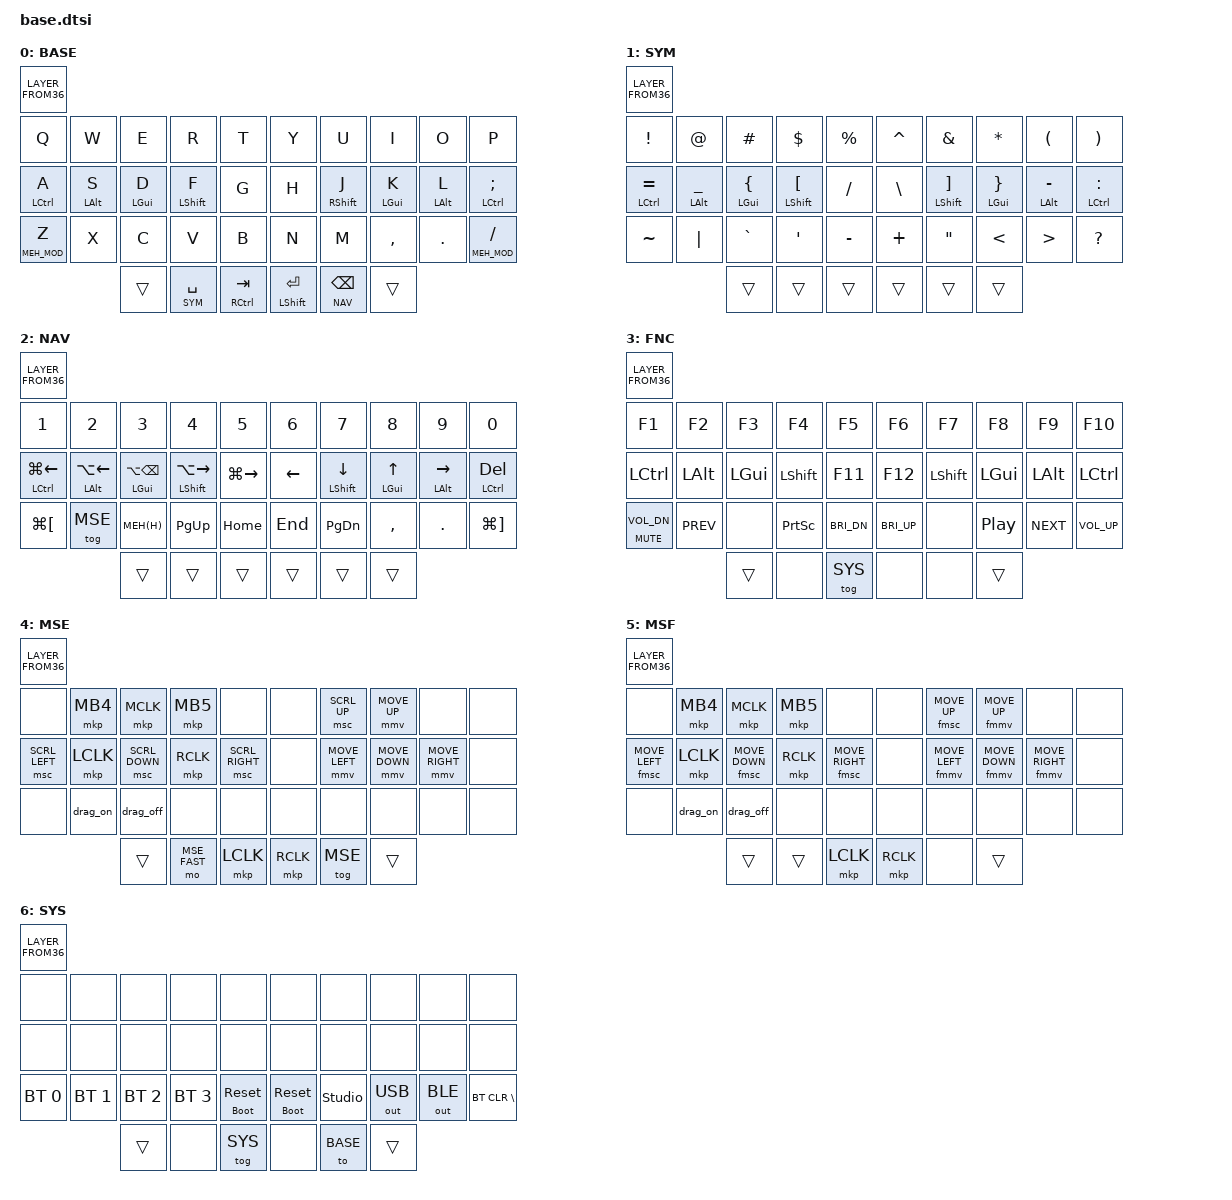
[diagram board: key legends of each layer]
#include <behaviors.dtsi>
#include <dt-bindings/zmk/keys.h>
#include <dt-bindings/zmk/bt.h>
#include <dt-bindings/zmk/outputs.h>
#include <behaviors/rgbled_widget.dtsi> // rgb led indicator for battery and connection

// Layer definitions
#define BASE 0
#define SYM 1
#define NAV 2
#define FNC 3
#define MSE 4
#define MSE_FAST 5
#define SYS 6

#define MEH(k) LC(LA(LS(k)))
#define MEH_MOD LA(LS(LCTRL))

#include "mouse.dtsi"
#include "combos.dtsi"

&caps_word { continue-list = <UNDERSCORE BACKSPACE DELETE MINUS DEL N1 N2 N3 N4 N5 N6 N7 N8 N9 N0>; };

/ {
    macros {
        drag_on: drag_on {
            compatible = "zmk,behavior-macro";
            #binding-cells = <0>;
            bindings = <&macro_press &mkp LCLK>;
        };

        drag_off: drag_off {
            compatible = "zmk,behavior-macro";
            #binding-cells = <0>;
            bindings = <&macro_release &mkp LCLK>;
        };
    };

   cond_layers {
        compatible = "zmk,conditional-layers";
        // Define FNC layer as tri-state
        func_tristate {
            if-layers = <SYM NAV>;
            then-layer = <FNC>;
        };
    };

    behaviors {
        hmr: hmr {
            compatible = "zmk,behavior-hold-tap";
            bindings = <&kp>, <&kp>;

            #binding-cells = <2>;
            tapping-term-ms = <230>;
            quick-tap-ms = <150>;
            require-prior-idle-ms = <130>;
            flavor = "balanced";
            hold-trigger-key-positions = <KEYS_L THUMBS>;
            hold-trigger-on-release;
        };

        hml: hml {
            compatible = "zmk,behavior-hold-tap";
            bindings = <&kp>, <&kp>;

            #binding-cells = <2>;
            tapping-term-ms = <230>;
            quick-tap-ms = <155>;
            require-prior-idle-ms = <130>;
            flavor = "balanced";
            hold-trigger-key-positions = <KEYS_R LH0 RH0 RH1>;
            hold-trigger-on-release;
        };

        rth: rthumb {
            compatible = "zmk,behavior-hold-tap";
            bindings = <&mo>, <&kp>;
            flavor = "hold-preferred";
            #binding-cells = <2>;
            tapping-term-ms = <200>;
            quick-tap-ms = <130>;
        };

        lth: lthumb {
            compatible = "zmk,behavior-hold-tap";
            bindings = <&mo>, <&kp>;
            flavor = "hold-preferred";
            #binding-cells = <2>;
            tapping-term-ms = <230>;
            quick-tap-ms = <140>;
        };

        hp: hold_priority {
            compatible = "zmk,behavior-hold-tap";
            bindings = <&kp>, <&kp>;
            flavor = "hold-preferred";
            #binding-cells = <2>;
            tapping-term-ms = <230>;
            quick-tap-ms = <150>;
        };

        lsm: left_shift_mode {
            compatible = "zmk,behavior-hold-tap";
            bindings = <&kp>, <&kp>;
            flavor = "hold-preferred";
            #binding-cells = <2>;
            tapping-term-ms = <190>;
            quick-tap-ms = <150>;
            require-prior-idle-ms = <120>;
            hold-trigger-key-positions = <KEYS_R LH0 RH0>;
            //hold-trigger-on-release;
        };

        rsm: right_shift_mode {
            compatible = "zmk,behavior-hold-tap";
            bindings = <&kp>, <&kp>;
            flavor = "hold-preferred";
            #binding-cells = <2>;
            tapping-term-ms = <190>;
            quick-tap-ms = <150>;
            require-prior-idle-ms = <130>;
            hold-trigger-key-positions = <KEYS_L LH0 RH0>;
            //hold-trigger-on-release;
        };

        rst_boot: rst_boot {
            compatible = "zmk,behavior-hold-tap";
            #binding-cells = <2>;
            tapping-term-ms = <800>;
            flavor = "tap-preferred";
            bindings = <&bootloader>, <&sys_reset>; // Press-> sys_reset, hold-> bootloader
        };

    };

    keymap {
        compatible = "zmk,keymap";

        base {
            display-name = "BASE";
            bindings = <LAYER_FROM36( \
// ╭─────────────┬─────────────┬─────────────┬─────────────┬─────────────╮   ╭───────────────┬───────────────┬───────────────┬─────────────┬───────────────╮
     &kp Q,        &kp W,        &kp E,        &kp R,        &kp T,            &kp Y,           &kp U,          &kp I,        &kp O,           &kp P,      \
// ├─────────────┼─────────────┼─────────────┼─────────────┼─────────────┤   ├───────────────┼───────────────┼───────────────┼─────────────┼───────────────┤
     &hml LCTRL A, &hml LALT S,  &hml LGUI D,  &lsm LSHFT F, &kp G,            &kp H,           &rsm RSHFT J, &hmr LGUI K,    &hmr LALT L,  &hmr LCTRL SEMI,\
// ├─────────────┼─────────────┼─────────────┼─────────────┼─────────────┤   ├───────────────┼───────────────┼───────────────┼─────────────┼───────────────┤
     &hml MEH_MOD Z,             &kp X,        &kp C,        &kp V,        &kp B,            &kp N,           &kp M,          &kp COMMA,      &kp DOT,     &hmr MEH_MOD SLASH, \
// ╰─────────────┴─────────────┴─────────────┼─────────────┼─────────────┤   ├───────────────┼───────────────┼───────────────┴─────────────┴───────────────╯
                                 &trans,      &lth SYM SPACE, &hp RCTRL TAB,  &hp LSHFT ENTER,  &rth NAV BSPC,   &trans
//                             ╰─────────────┴─────────────┴─────────────╯   ╰───────────────┴───────────────┴─────────────╯
            )>;
        };

        symbol {
          display-name = "SYM";
          bindings = <LAYER_FROM36( \
// ╭───────────────┬───────────────┬───────────────┬────────────────────┬───────────────╮   ╭───────────────┬────────────────────┬────────────────────┬────────────────────┬────────────────────╮
    &kp EXCL,        &kp AT_SIGN,     &kp HASH,        &kp DLLR,           &kp PRCNT,         &kp CARET,       &kp AMPS,            &kp ASTERISK,          &kp LPAR,             &kp RPAR,      \
// ├───────────────┼───────────────┼───────────────┼────────────────────┼───────────────┤   ├───────────────┼────────────────────┼────────────────────┼────────────────────┼────────────────────┤
   &hml LCTRL EQUAL, &hml LALT UNDER, &hml LGUI LBRC, &hml LSHFT LBKT,    &kp SLASH,          &kp BSLH,        &hmr LSHFT RBKT,    &hmr LGUI RBRC,       &hmr LALT MINUS,     &hmr LCTRL COLON, \
// ├───────────────┼───────────────┼───────────────┼────────────────────┼───────────────┤   ├───────────────┼────────────────────┼────────────────────┼────────────────────┼────────────────────┤
      &kp TILDE,       &kp PIPE,       &kp GRAVE,       &kp SQT,            &kp MINUS,         &kp PLUS,        &kp DOUBLE_QUOTES,  &kp LESS_THAN,       &kp GREATER_THAN,     &kp QUESTION,    \
// ╰───────────────┴───────────────┴───────────────┼────────────────────┼───────────────┤   ├───────────────┼────────────────────┴────────────────────┴────────────────────┴────────────────────╯
                                       &trans,          &trans,             &trans,              &trans,        &trans,             &trans       \
//                                 ╰───────────────┴────────────────────┴───────────────╯   ╰───────────────┴────────────────────┴───────────────╯
         )>;
      };

        nav_number {
            display-name = "NAV";
            bindings = <LAYER_FROM36( \
// ╭──────────────────┬───────────────┬────────────────────┬─────────────────┬──────────────╮   ╭────────────────────┬─────────────────┬───────────────┬──────────────────┬─────────────────────╮
     &kp N1,               &kp N2,      &kp N3,              &kp N4,           &kp N5,             &kp N6,             &kp N7,            &kp N8,        &kp N9,            &kp N0,             \
// ├──────────────────┼───────────────┼────────────────────┼─────────────────┼──────────────┤   ├────────────────────┼─────────────────┼───────────────┼──────────────────┼─────────────────────┤
     &hml LCTRL LG(LEFT), &hml LALT LA(LEFT), &hml LGUI LA(BSPC),  &lsm LSHFT LA(RIGHT),  &kp LG(RIGHT),            &kp LEFT,           &hmr LSHFT DOWN,   &hmr LGUI UP,  &hmr LALT RIGHT,   &hmr LCTRL DEL,\
// ├──────────────────┼───────────────┼────────────────────┼─────────────────┼──────────────┤   ├────────────────────┼─────────────────┼───────────────┼──────────────────┼─────────────────────┤
     &kp LG(LBKT),        &tog MSE,      &kp MEH(H),                  &kp PG_UP,        &kp HOME,           &kp END,            &kp PG_DN,         &kp COMMA,      &kp DOT,          &kp LG(RBKT),      \
// ╰──────────────────┴───────────────┴────────────────────┼─────────────────┼──────────────┤   ├────────────────────┴─────────────────┴───────────────┴──────────────────┴─────────────────────╯
                                              &trans,        &trans,           &trans,             &trans,               &trans,              &trans   \
//                                    ╰────────────────────┴─────────────────┴──────────────╯   ╰────────────────────┴─────────────────┴───────────────╯
        )>;
      };

        settings_function {
            display-name = "FNC";
            bindings = <LAYER_FROM36( \
// ╭────────────────────┬────────────────────┬────────────────────┬────────────────────┬────────────────────╮   ╭─────────────────┬─────────────────┬───────────────┬───────────────┬────────────────────╮
     &kp F1,               &kp F2,               &kp F3,               &kp F4,             &kp F5,                 &kp F6,           &kp F7,          &kp F8,          &kp F9,          &kp F10,         \
// ├────────────────────┼────────────────────┼────────────────────┼────────────────────┼────────────────────┤   ├─────────────────┼─────────────────┼───────────────┼───────────────┼────────────────────┤
     &kp LCTRL,            &kp LALT,             &kp LGUI,             &kp LSHFT,         &kp F11,                 &kp F12,          &kp LSHFT,       &kp LGUI,        &kp LALT,        &kp LCTRL,       \
// ├────────────────────┼────────────────────┼────────────────────┼────────────────────┼────────────────────┤   ├─────────────────┼─────────────────┼───────────────┼───────────────┼────────────────────┤
     &hp C_MUTE C_VOL_DN, &kp C_PREV,            &none,                &kp PSCRN,         &kp C_BRI_DN,            &kp C_BRI_UP,      &none,           &kp C_PP,        &kp C_NEXT,      &kp C_VOL_UP,    \
// ╰────────────────────┴────────────────────┴────────────────────┼────────────────────┼────────────────────┤   ├─────────────────┴─────────────────┴───────────────┴───────────────┴────────────────────╯
                                                &trans,               &none,               &tog SYS,               &none,            &none,           &trans         \
//                                           ╰────────────────────┴────────────────────┴────────────────────╯   ╰─────────────────┴─────────────────┴────────────────╯
         )>;
      };

        mouse_layer {
            display-name = "MSE";
            bindings = <LAYER_FROM36( \
// ╭────────────────────┬───────────────┬────────────────────┬───────────────┬────────────────────╮   ╭─────────────────┬────────────────────┬────────────────────┬────────────────────┬────────────────────╮
     &none,               &mkp MB4,         &mkp MCLK,          &mkp MB5,      &none,                   &none,                &msc SCRL_UP,       &mmv MOVE_UP,       &none,                 &none,         \
// ├────────────────────┼───────────────┼────────────────────┼───────────────┼────────────────────┤   ├─────────────────┼────────────────────┼────────────────────┼────────────────────┼────────────────────┤
     &msc SCRL_LEFT,      &mkp LCLK,        &msc SCRL_DOWN,     &mkp RCLK,     &msc SCRL_RIGHT,         &none,                &mmv MOVE_LEFT,     &mmv MOVE_DOWN,    &mmv MOVE_RIGHT,        &none,         \
// ├────────────────────┼───────────────┼────────────────────┼───────────────┼────────────────────┤   ├─────────────────┼────────────────────┼────────────────────┼────────────────────┼────────────────────┤
     &none,               &drag_on,            &drag_off,          &none,         &none,                &none,                &none,                 &none,         &none,                  &none,         \
// ╰────────────────────┴───────────────┴────────────────────┼───────────────┼────────────────────┤   ├─────────────────┴────────────────────┴────────────────────┴────────────────────┴────────────────────╯
                                                &trans,         &mo MSE_FAST,  &mkp LCLK,               &mkp RCLK,            &tog MSE,              &trans       \
//                                      ╰────────────────────┴───────────────┴────────────────────╯   ╰─────────────────┴────────────────────┴────────────────────╯
         )>;
        };

        mouse_layer_fast {
            display-name = "MSF";
            bindings = <LAYER_FROM36( \
// ╭────────────────────┬───────────────┬────────────────────┬───────────────┬────────────────────╮   ╭─────────────────┬────────────────────┬────────────────────┬────────────────────┬────────────────────╮
     &none,               &mkp MB4,         &mkp MCLK,          &mkp MB5,      &none,                   &none,                &fmsc MOVE_UP,      &fmmv MOVE_UP,      &none,                 &none,         \
// ├────────────────────┼───────────────┼────────────────────┼───────────────┼────────────────────┤   ├─────────────────┼────────────────────┼────────────────────┼────────────────────┼────────────────────┤
     &fmsc MOVE_LEFT,     &mkp LCLK,        &fmsc MOVE_DOWN,    &mkp RCLK,     &fmsc MOVE_RIGHT,        &none,                &fmmv MOVE_LEFT,    &fmmv MOVE_DOWN,   &fmmv MOVE_RIGHT,       &none,         \
// ├────────────────────┼───────────────┼────────────────────┼───────────────┼────────────────────┤   ├─────────────────┼────────────────────┼────────────────────┼────────────────────┼────────────────────┤
     &none,               &drag_on,            &drag_off,          &none,         &none,                &none,                &none,              &none,            &none,                  &none,         \
// ╰────────────────────┴───────────────┴────────────────────┼───────────────┼────────────────────┤   ├─────────────────┴────────────────────┴────────────────────┴────────────────────┴────────────────────╯
                                                &trans,         &trans,        &mkp LCLK,               &mkp RCLK,            &none,              &trans       \
//                                      ╰────────────────────┴───────────────┴────────────────────╯   ╰─────────────────┴────────────────────┴────────────────────╯
         )>;
        };

        system_layer {
            display-name = "SYS";
            bindings = <LAYER_FROM36( \
// ╭────────────────────┬────────────────────┬────────────────────┬────────────────────┬────────────────────╮   ╭─────────────────┬─────────────────┬───────────────┬───────────────┬────────────────────╮
     &none,               &none,               &none,               &none,               &none,                  &none,             &none,           &none,          &none,          &none,          \
// ├────────────────────┼────────────────────┼────────────────────┼────────────────────┼────────────────────┤   ├─────────────────┼─────────────────┼───────────────┼───────────────┼────────────────────┤
     &none,               &none,               &none,               &none,               &none,                  &none,             &none,           &none,          &none,          &none,          \
// ├────────────────────┼────────────────────┼────────────────────┼────────────────────┼────────────────────┤   ├─────────────────┼─────────────────┼───────────────┼───────────────┼────────────────────┤
     &bt BT_SEL 0,        &bt BT_SEL 1,        &bt BT_SEL 2,        &bt BT_SEL 3,        &rst_boot 0 0,          &rst_boot 0 0,     &studio_unlock,  &out OUT_USB,   &out OUT_BLE,   &bt BT_CLR,     \
// ╰────────────────────┴────────────────────┴────────────────────┼────────────────────┼────────────────────┤   ├─────────────────┴─────────────────┴───────────────┴───────────────┴────────────────────╯
                                                &trans,              &none,               &tog SYS,              &none,            &to BASE,        &trans         \
//                                           ╰────────────────────┴────────────────────┴────────────────────╯   ╰─────────────────┴─────────────────┴────────────────╯
         )>;
      };
    };

};
